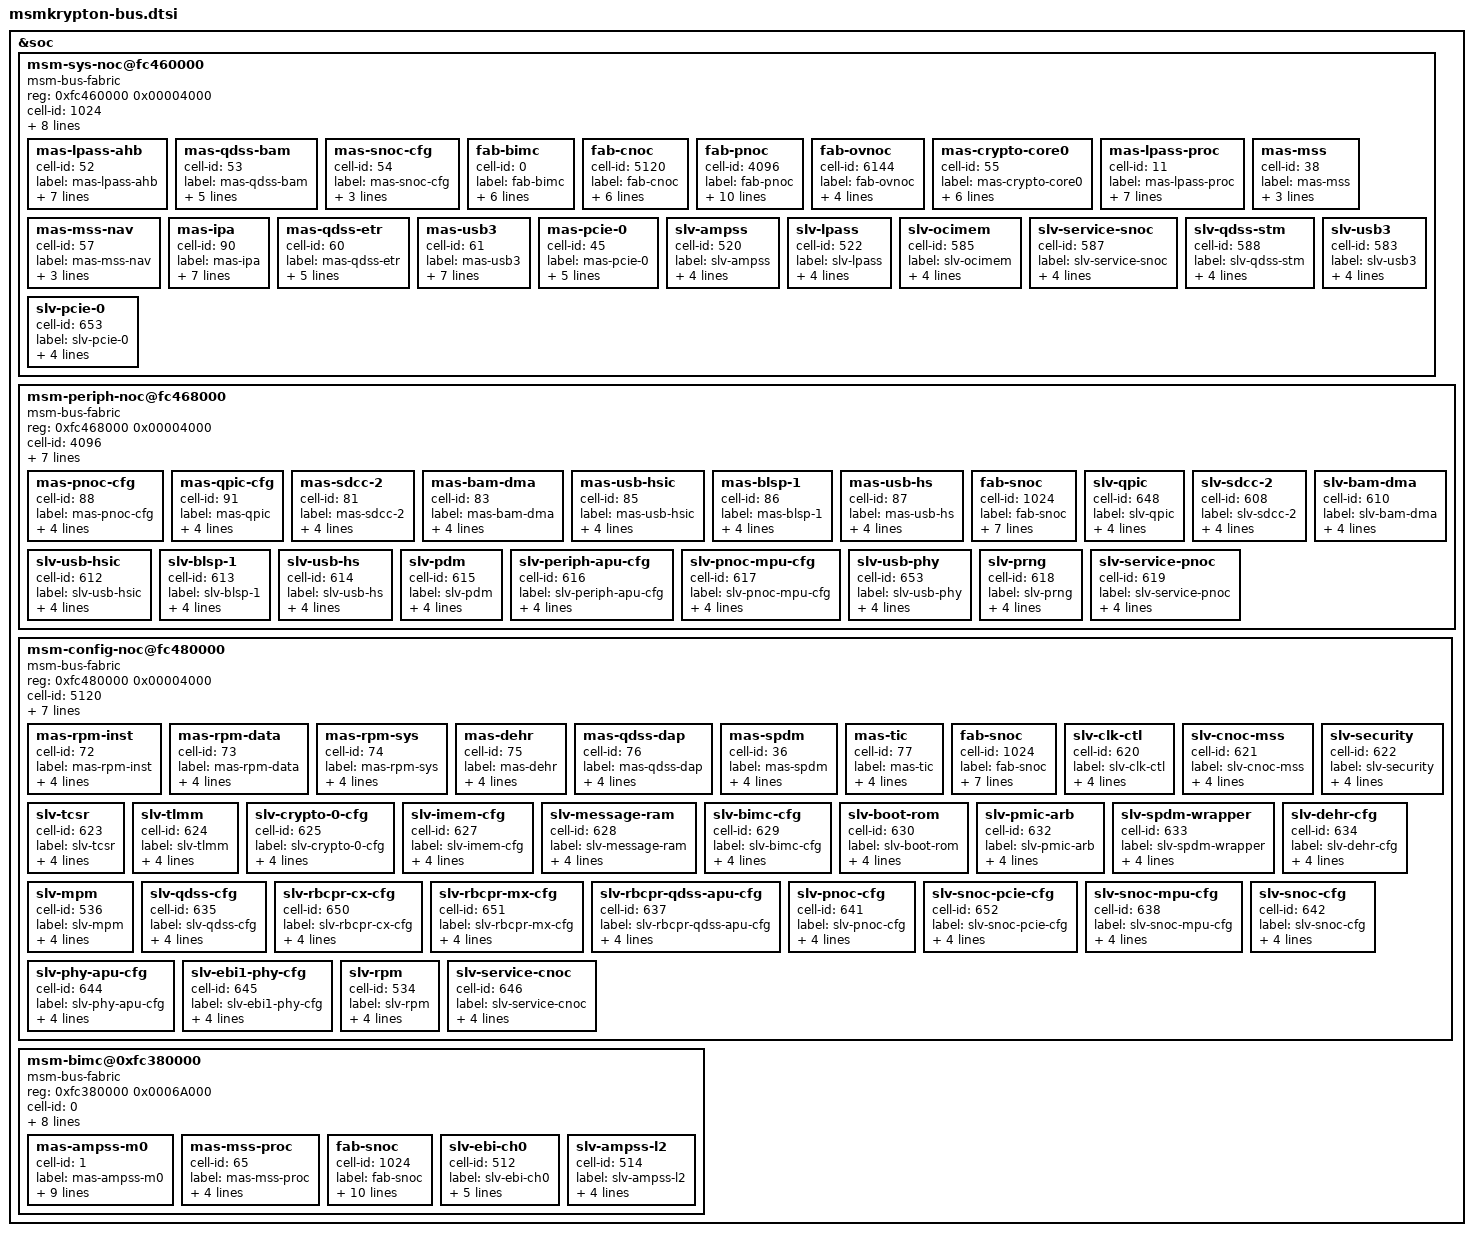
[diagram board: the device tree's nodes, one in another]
/* Copyright (c) 2013, The Linux Foundation. All rights reserved.
 *
 * This program is free software; you can redistribute it and/or modify
 * it under the terms of the GNU General Public License version 2 and
 * only version 2 as published by the Free Software Foundation.
 *
 * This program is distributed in the hope that it will be useful,
 * but WITHOUT ANY WARRANTY; without even the implied warranty of
 * MERCHANTABILITY or FITNESS FOR A PARTICULAR PURPOSE.  See the
 * GNU General Public License for more details.
 */

&soc {
	msm-sys-noc@fc460000 {
		compatible = "msm-bus-fabric";
		reg = <0xfc460000 0x00004000>;
		cell-id = <1024>;
		label = "msm_sys_noc";
		qcom,fabclk-dual = "bus_clk";
		qcom,fabclk-active = "bus_a_clk";
		qcom,ntieredslaves = <0>;
		qcom,qos-freq = <4800>;
		qcom,hw-sel = "NoC";
		qcom,rpm-en;
		qcom,nfab = <4>;

		mas-lpass-ahb {
			cell-id = <52>;
			label = "mas-lpass-ahb";
			qcom,masterp = <0>;
			qcom,tier = <2>;
			qcom,qport = <0>;
			qcom,mas-hw-id = <18>;
			qcom,mode = "Fixed";
			qcom,prio-rd = <2>;
			qcom,prio-wr = <2>;
		};

		mas-qdss-bam {
			cell-id = <53>;
			label = "mas-qdss-bam";
			qcom,masterp = <1>;
			qcom,tier = <2>;
			qcom,mode = "Fixed";
			qcom,qport = <1>;
			qcom,mas-hw-id = <19>;
		};

		mas-snoc-cfg {
			cell-id = <54>;
			label = "mas-snoc-cfg";
			qcom,masterp = <2>;
			qcom,tier = <2>;
			qcom,mas-hw-id = <20>;
		};

		fab-bimc {
			cell-id = <0>;
			label= "fab-bimc";
			qcom,gateway;
			qcom,slavep = <2>;
			qcom,masterp = <3>;
			qcom,buswidth = <8>;
			qcom,mas-hw-id = <21>;
			qcom,slv-hw-id = <24>;
		};

		fab-cnoc {
			cell-id = <5120>;
			label = "fab-cnoc";
			qcom,gateway;
			qcom,slavep = <3>;
			qcom,masterp = <4>;
			qcom,buswidth = <8>;
			qcom,mas-hw-id = <22>;
			qcom,slv-hw-id = <25>;
		};

		fab-pnoc {
			cell-id = <4096>;
			label = "fab-pnoc";
			qcom,gateway;
			qcom,slavep = <5>;
			qcom,masterp = <11>;
			qcom,buswidth = <8>;
			qcom,qport = <8>;
			qcom,mas-hw-id = <29>;
			qcom,slv-hw-id = <28>;
			qcom,mode = "Fixed";
			qcom,prio-rd = <2>;
			qcom,prio-wr = <2>;
		};

		fab-ovnoc {
			cell-id = <6144>;
			label = "fab-ovnoc";
			qcom,gateway;
			qcom,buswidth = <8>;
			qcom,mas-hw-id = <53>;
			qcom,slv-hw-id = <77>;
		};

		mas-crypto-core0 {
			cell-id = <55>;
			label = "mas-crypto-core0";
			qcom,masterp = <5>;
			qcom,tier = <2>;
			qcom,mode = "Fixed";
			qcom,qport = <2>;
			qcom,mas-hw-id = <23>;
			qcom,hw-sel = "NoC";
		};

		mas-lpass-proc {
			cell-id = <11>;
			label = "mas-lpass-proc";
			qcom,masterp = <7>;
			qcom,tier = <2>;
			qcom,qport = <4>;
			qcom,mas-hw-id = <25>;
			qcom,mode = "Fixed";
			qcom,prio-rd = <2>;
			qcom,prio-wr = <2>;
		};

		mas-mss {
			cell-id = <38>;
			label = "mas-mss";
			qcom,masterp = <8>;
			qcom,tier = <2>;
			qcom,mas-hw-id = <26>;
		};

		mas-mss-nav {
			cell-id = <57>;
			label = "mas-mss-nav";
			qcom,masterp = <9>;
			qcom,tier = <2>;
			qcom,mas-hw-id = <27>;
		};

		mas-ipa {
			cell-id = <90>;
			label = "mas-ipa";
			qcom,masterp = <6>;
			qcom,tier = <2>;
			qcom,mode = "Fixed";
			qcom,qport = <6>;
			qcom,mas-hw-id = <59>;
			qcom,hw-sel = "NoC";
			qcom,iface-clk-node = "msm_ipa";
		};

		mas-qdss-etr {
			cell-id = <60>;
			label = "mas-qdss-etr";
			qcom,masterp = <12>;
			qcom,tier = <2>;
			qcom,qport = <10>;
			qcom,mode = "Fixed";
			qcom,mas-hw-id = <31>;
		};

		mas-usb3 {
			cell-id = <61>;
			label = "mas-usb3";
			qcom,masterp = <10>;
			qcom,tier = <2>;
			qcom,qport = <7>;
			qcom,mode = "Fixed";
			qcom,mas-hw-id = <32>;
			qcom,hw-sel = "NoC";
			qcom,iface-clk-node = "msm_usb3";
		};

		mas-pcie-0 {
			cell-id = <45>;
			label = "mas-pcie-0";
			qcom,masterp = <13>;
			qcom,tier = <2>;
			qcom,qport = <10>;
			qcom,mode = "Fixed";
			qcom,mas-hw-id = <65>;
		};

		slv-ampss {
			cell-id = <520>;
			label = "slv-ampss";
			qcom,slavep = <0>;
			qcom,tier = <2>;
			qcom,buswidth = <8>;
			qcom,slv-hw-id = <20>;
		};

		slv-lpass {
			cell-id = <522>;
			label = "slv-lpass";
			qcom,slavep = <1>;
			qcom,tier = <2>;
			qcom,buswidth = <8>;
			qcom,slv-hw-id = <21>;
		};

		slv-ocimem {
			cell-id = <585>;
			label = "slv-ocimem";
			qcom,slavep = <4>;
			qcom,tier = <2>;
			qcom,buswidth = <8>;
			qcom,slv-hw-id = <26>;
		};

		slv-service-snoc {
			cell-id = <587>;
			label = "slv-service-snoc";
			qcom,slavep = <6>;
			qcom,tier = <2>;
			qcom,buswidth = <8>;
			qcom,slv-hw-id = <29>;
		};

		slv-qdss-stm {
			cell-id = <588>;
			label = "slv-qdss-stm";
			qcom,slavep = <7>;
			qcom,tier = <2>;
			qcom,buswidth = <8>;
			qcom,slv-hw-id = <30>;
		};

		slv-usb3 {
			cell-id = <583>;
			label = "slv-usb3";
			qcom,slavep = <9>;
			qcom,tier = <2>;
			qcom,buswidth = <8>;
			qcom,slv-hw-id = <22>;
		};

		slv-pcie-0 {
			cell-id = <653>;
			label = "slv-pcie-0";
			qcom,slavep = <8>;
			qcom,tier = <2>;
			qcom,buswidth = <8>;
			qcom,slv-hw-id = <85>;
		};

	};

	msm-periph-noc@fc468000 {
		compatible = "msm-bus-fabric";
		reg = <0xfc468000 0x00004000>;
		cell-id = <4096>;
		label = "msm_periph_noc";
		qcom,fabclk-dual = "bus_clk";
		qcom,fabclk-active = "bus_a_clk";
		qcom,ntieredslaves = <0>;
		qcom,hw-sel = "NoC";
		qcom,nfab = <4>;
		qcom,rpm-en;

		mas-pnoc-cfg {
			cell-id = <88>;
			label = "mas-pnoc-cfg";
			qcom,masterp = <7>;
			qcom,tier = <2>;
			qcom,buswidth = <8>;
			qcom,mas-hw-id = <43>;
		};

		mas-qpic-cfg {
			cell-id = <91>;
			label = "mas-qpic";
			qcom,masterp = <1>;
			qcom,tier = <2>;
			qcom,buswidth = <8>;
			qcom,mas-hw-id = <58>;
		};

		mas-sdcc-2 {
			cell-id = <81>;
			label = "mas-sdcc-2";
			qcom,masterp = <2>;
			qcom,tier = <2>;
			qcom,buswidth = <8>;
			qcom,mas-hw-id = <35>;
		};

		mas-bam-dma {
			cell-id = <83>;
			label = "mas-bam-dma";
			qcom,masterp = <3>;
			qcom,tier = <2>;
			qcom,buswidth = <8>;
			qcom,mas-hw-id = <38>;
		};

		mas-usb-hsic {
			cell-id = <85>;
			label = "mas-usb-hsic";
			qcom,masterp = <4>;
			qcom,tier = <2>;
			qcom,buswidth = <8>;
			qcom,mas-hw-id = <40>;
		};

		mas-blsp-1 {
			cell-id = <86>;
			label = "mas-blsp-1";
			qcom,masterp = <5>;
			qcom,tier = <2>;
			qcom,buswidth = <8>;
			qcom,mas-hw-id = <41>;
		};

		mas-usb-hs {
			cell-id = <87>;
			label = "mas-usb-hs";
			qcom,masterp = <6>;
			qcom,tier = <2>;
			qcom,buswidth = <8>;
			qcom,mas-hw-id = <42>;
		};

		fab-snoc {
			cell-id = <1024>;
			label = "fab-snoc";
			qcom,gateway;
			qcom,slavep = <12>;
			qcom,masterp = <8>;
			qcom,tier = <2>;
			qcom,buswidth = <8>;
			qcom,slv-hw-id = <45>;
			qcom,mas-hw-id = <44>;
		};

		slv-qpic {
			cell-id = <648>;
			label = "slv-qpic";
			qcom,slavep = <2>;
			qcom,tier = <2>;
			qcom,buswidth = <8>;
			qcom,slv-hw-id = <81>;
		};

		slv-sdcc-2 {
			cell-id = <608>;
			label = "slv-sdcc-2";
			qcom,slavep = <1>;
			qcom,tier = <2>;
			qcom,buswidth = <8>;
			qcom,slv-hw-id = <33>;
		};

		slv-bam-dma {
			cell-id = <610>;
			label = "slv-bam-dma";
			qcom,slavep = <2>;
			qcom,tier = <2>;
			qcom,buswidth = <8>;
			qcom,slv-hw-id = <36>;
		};

		slv-usb-hsic {
			cell-id = <612>;
			label = "slv-usb-hsic";
			qcom,slavep = <3>;
			qcom,tier = <2>;
			qcom,buswidth = <8>;
			qcom,slv-hw-id = <38>;
		};

		slv-blsp-1 {
			cell-id = <613>;
			label = "slv-blsp-1";
			qcom,slavep = <5>;
			qcom,tier = <2>;
			qcom,buswidth = <8>;
			qcom,slv-hw-id = <39>;
		};

		slv-usb-hs {
			cell-id = <614>;
			label = "slv-usb-hs";
			qcom,slavep = <5>;
			qcom,tier = <2>;
			qcom,buswidth = <8>;
			qcom,slv-hw-id = <40>;
		};

		slv-pdm	{
			cell-id = <615>;
			label = "slv-pdm";
			qcom,slavep = <6>;
			qcom,tier = <2>;
			qcom,buswidth = <8>;
			qcom,slv-hw-id = <41>;
		};

		slv-periph-apu-cfg {
			cell-id = <616>;
			label = "slv-periph-apu-cfg";
			qcom,slavep = <7>;
			qcom,tier = <2>;
			qcom,buswidth = <8>;
			qcom,slv-hw-id = <42>;
		};

		slv-pnoc-mpu-cfg {
			cell-id = <617>;
			label = "slv-pnoc-mpu-cfg";
			qcom,slavep = <8>;
			qcom,tier = <2>;
			qcom,buswidth = <8>;
			qcom,slv-hw-id = <43>;
		};

		slv-usb-phy {
			cell-id = <653>;
			label = "slv-usb-phy";
			qcom,slavep = <9>;
			qcom,tier = <2>;
			qcom,buswidth = <8>;
			qcom,slv-hw-id = <95>;
		};

		slv-prng {
			cell-id = <618>;
			label = "slv-prng";
			qcom,slavep = <10>;
			qcom,tier = <2>;
			qcom,buswidth = <8>;
			qcom,slv-hw-id = <44>;
		};

		slv-service-pnoc {
			cell-id = <619>;
			label = "slv-service-pnoc";
			qcom,slavep = <12>;
			qcom,tier = <2>;
			qcom,buswidth = <8>;
			qcom,slv-hw-id = <46>;
		};

	};

	msm-config-noc@fc480000 {
		compatible = "msm-bus-fabric";
		reg = <0xfc480000 0x00004000>;
		cell-id = <5120>;
		label = "msm_config_noc";
		qcom,fabclk-dual = "bus_clk";
		qcom,fabclk-active = "bus_a_clk";
		qcom,ntieredslaves = <0>;
		qcom,hw-sel = "NoC";
		qcom,nfab = <4>;
		qcom,rpm-en;

		mas-rpm-inst {
			cell-id = <72>;
			label = "mas-rpm-inst";
			qcom,masterp = <0>;
			qcom,tier = <2>;
			qcom,buswidth = <8>;
			qcom,mas-hw-id = <45>;
		};

		mas-rpm-data {
			cell-id = <73>;
			label = "mas-rpm-data";
			qcom,masterp = <1>;
			qcom,tier = <2>;
			qcom,buswidth = <8>;
			qcom,mas-hw-id = <46>;
		};

		mas-rpm-sys {
			cell-id = <74>;
			label = "mas-rpm-sys";
			qcom,masterp = <2>;
			qcom,tier = <2>;
			qcom,buswidth = <8>;
			qcom,mas-hw-id = <47>;
		};

		mas-dehr {
			cell-id = <75>;
			label = "mas-dehr";
			qcom,masterp = <3>;
			qcom,tier = <2>;
			qcom,buswidth = <8>;
			qcom,mas-hw-id = <48>;
		};

		mas-qdss-dap {
			cell-id = <76>;
			label = "mas-qdss-dap";
			qcom,masterp = <4>;
			qcom,tier = <2>;
			qcom,buswidth = <8>;
			qcom,mas-hw-id = <49>;
		};

		mas-spdm {
			cell-id = <36>;
			label = "mas-spdm";
			qcom,masterp = <5>;
			qcom,tier = <2>;
			qcom,buswidth = <8>;
			qcom,mas-hw-id = <50>;
		};

		mas-tic	{
			cell-id = <77>;
			label = "mas-tic";
			qcom,masterp = <6>;
			qcom,tier = <2>;
			qcom,buswidth = <8>;
			qcom,mas-hw-id = <51>;
		};

		fab-snoc {
			cell-id = <1024>;
			label = "fab-snoc";
			qcom,gateway;
			qcom,slavep = <26>;
			qcom,masterp = <7>;
			qcom,tier = <2>;
			qcom,buswidth = <8>;
			qcom,mas-hw-id = <52>;
			qcom,slv-hw-id = <75>;
		};

		slv-clk-ctl {
			cell-id = <620>;
			label = "slv-clk-ctl";
			qcom,slavep = <0>;
			qcom,tier = <2>;
			qcom,buswidth = <8>;
			qcom,slv-hw-id = <47>;
		};

		slv-cnoc-mss {
			cell-id = <621>;
			label = "slv-cnoc-mss";
			qcom,slavep = <1>;
			qcom,tier = <2>;
			qcom,buswidth = <8>;
			qcom,slv-hw-id = <48>;
		};

		slv-security {
			cell-id = <622>;
			label = "slv-security";
			qcom,slavep = <2>;
			qcom,tier = <2>;
			qcom,buswidth = <8>;
			qcom,slv-hw-id = <49>;
		};

		slv-tcsr {
			cell-id = <623>;
			label = "slv-tcsr";
			qcom,slavep = <3>;
			qcom,tier = <2>;
			qcom,buswidth = <8>;
			qcom,slv-hw-id = <50>;
		};

		slv-tlmm {
			cell-id = <624>;
			label = "slv-tlmm";
			qcom,slavep = <4>;
			qcom,tier = <2>;
			qcom,buswidth = <8>;
			qcom,slv-hw-id = <51>;
		};

		slv-crypto-0-cfg {
			cell-id = <625>;
			label = "slv-crypto-0-cfg";
			qcom,slavep = <5>;
			qcom,tier = <2>;
			qcom,buswidth = <8>;
			qcom,slv-hw-id = <52>;
		};

		slv-imem-cfg {
			cell-id = <627>;
			label = "slv-imem-cfg";
			qcom,slavep = <6>;
			qcom,tier = <2>;
			qcom,buswidth = <8>;
			qcom,slv-hw-id = <54>;
		};

		slv-message-ram	{
			cell-id = <628>;
			label = "slv-message-ram";
			qcom,slavep = <7>;
			qcom,tier = <2>;
			qcom,buswidth = <8>;
			qcom,slv-hw-id = <55>;
		};

		slv-bimc-cfg {
			cell-id = <629>;
			label = "slv-bimc-cfg";
			qcom,slavep = <8>;
			qcom,tier = <2>;
			qcom,buswidth = <8>;
			qcom,slv-hw-id = <56>;
		};

		slv-boot-rom {
			cell-id = <630>;
			label = "slv-boot-rom";
			qcom,slavep = <9>;
			qcom,tier = <2>;
			qcom,buswidth = <8>;
			qcom,slv-hw-id = <57>;
		};

		slv-pmic-arb {
			cell-id = <632>;
			label = "slv-pmic-arb";
			qcom,slavep = <10>;
			qcom,tier = <2>;
			qcom,buswidth = <8>;
			qcom,slv-hw-id = <59>;
		};

		slv-spdm-wrapper {
			cell-id = <633>;
			label = "slv-spdm-wrapper";
			qcom,slavep = <11>;
			qcom,tier = <2>;
			qcom,buswidth = <8>;
			qcom,slv-hw-id = <60>;
		};

		slv-dehr-cfg {
			cell-id = <634>;
			label = "slv-dehr-cfg";
			qcom,slavep = <12>;
			qcom,tier = <2>;
			qcom,buswidth = <8>;
			qcom,slv-hw-id = <61>;
		};

		slv-mpm	{
			cell-id = <536>;
			label = "slv-mpm";
			qcom,slavep = <13>;
			qcom,tier = <2>;
			qcom,buswidth = <8>;
			qcom,slv-hw-id = <62>;
		};

		slv-qdss-cfg {
			cell-id = <635>;
			label = "slv-qdss-cfg";
			qcom,slavep = <14>;
			qcom,tier = <2>;
			qcom,buswidth = <8>;
			qcom,slv-hw-id = <63>;
		};

		slv-rbcpr-cx-cfg {
			cell-id = <650>;
			label = "slv-rbcpr-cx-cfg";
			qcom,slavep = <15>;
			qcom,tier = <2>;
			qcom,buswidth = <8>;
			qcom,slv-hw-id = <64>;
		};

		slv-rbcpr-mx-cfg {
			cell-id = <651>;
			label = "slv-rbcpr-mx-cfg";
			qcom,slavep = <16>;
			qcom,tier = <2>;
			qcom,buswidth = <8>;
			qcom,slv-hw-id = <96>;
		};

		slv-rbcpr-qdss-apu-cfg {
			cell-id = <637>;
			label = "slv-rbcpr-qdss-apu-cfg";
			qcom,slavep = <17>;
			qcom,tier = <2>;
			qcom,buswidth = <8>;
			qcom,slv-hw-id = <65>;
		};

		slv-pnoc-cfg {
			cell-id = <641>;
			label = "slv-pnoc-cfg";
			qcom,slavep = <20>;
			qcom,tier = <2>;
			qcom,buswidth = <8>;
			qcom,slv-hw-id = <69>;
		};

		slv-snoc-pcie-cfg {
			cell-id = <652>;
			label = "slv-snoc-pcie-cfg";
			qcom,slavep = <18>;
			qcom,tier = <2>;
			qcom,buswidth = <8>;
			qcom,slv-hw-id = <67>;
		};

		slv-snoc-mpu-cfg {
			cell-id = <638>;
			label = "slv-snoc-mpu-cfg";
			qcom,slavep = <19>;
			qcom,tier = <2>;
			qcom,buswidth = <8>;
			qcom,slv-hw-id = <67>;
		};

		slv-snoc-cfg {
			cell-id = <642>;
			label = "slv-snoc-cfg";
			qcom,slavep = <21>;
			qcom,tier = <2>;
			qcom,buswidth = <8>;
			qcom,slv-hw-id = <70>;
		};

		slv-phy-apu-cfg {
			cell-id = <644>;
			label = "slv-phy-apu-cfg";
			qcom,slavep = <22>;
			qcom,tier = <2>;
			qcom,buswidth = <8>;
			qcom,slv-hw-id = <72>;
		};

		slv-ebi1-phy-cfg {
			cell-id = <645>;
			label = "slv-ebi1-phy-cfg";
			qcom,slavep = <23>;
			qcom,tier = <2>;
			qcom,buswidth = <8>;
			qcom,slv-hw-id = <73>;
		};

		slv-rpm {
			cell-id = <534>;
			label = "slv-rpm";
			qcom,slavep = <24>;
			qcom,tier = <2>;
			qcom,buswidth = <8>;
			qcom,slv-hw-id = <74>;
		};

		slv-service-cnoc {
			cell-id = <646>;
			label = "slv-service-cnoc";
			qcom,slavep = <26>;
			qcom,tier = <2>;
			qcom,buswidth = <8>;
			qcom,slv-hw-id = <76>;
		};

	};

	msm-bimc@0xfc380000 {
		compatible = "msm-bus-fabric";
		reg = <0xfc380000 0x0006A000>;
		cell-id = <0>;
		label = "msm_bimc";
		qcom,fabclk-dual = "mem_clk";
		qcom,fabclk-active = "mem_a_clk";
		qcom,ntieredslaves = <0>;
		qcom,qos-freq = <4800>;
		qcom,hw-sel = "BIMC";
		qcom,nfab = <4>;
		qcom,rpm-en;

		mas-ampss-m0 {
			cell-id = <1>;
			label = "mas-ampss-m0";
			qcom,masterp = <0>;
			qcom,tier = <2>;
			qcom,hw-sel = "BIMC";
			qcom,mode = "Fixed";
			qcom,qport = <0>;
			qcom,ws = <10000>;
			qcom,mas-hw-id = <0>;
			qcom,prio-rd = <0>;
			qcom,prio-wr = <0>;
		};

		mas-mss-proc {
			cell-id = <65>;
			label = "mas-mss-proc";
			qcom,masterp = <1>;
			qcom,tier = <2>;
			qcom,hw-sel = "RPM";
			qcom,mas-hw-id = <1>;
		};

		fab-snoc {
			cell-id = <1024>;
			label = "fab-snoc";
			qcom,gateway;
			qcom,slavep = <1>;
			qcom,masterp = <2>;
			qcom,qport = <4>;
			qcom,buswidth = <8>;
			qcom,ws = <10000>;
			qcom,mas-hw-id = <3>;
			qcom,slv-hw-id = <2>;
			qcom,mode = "Bypass";
			qcom,hw-sel = "RPM";
		};

		slv-ebi-ch0 {
			cell-id = <512>;
			label = "slv-ebi-ch0";
			qcom,slavep = <0>;
			qcom,tier = <2>;
			qcom,buswidth = <8>;
			qcom,slv-hw-id = <0>;
			qcom,mode = "Bypass";
		};

		slv-ampss-l2 {
			cell-id = <514>;
			label = "slv-ampss-l2";
			qcom,slavep = <1>;
			qcom,tier = <2>;
			qcom,buswidth = <8>;
			qcom,slv-hw-id = <1>;
		};
	};

};


